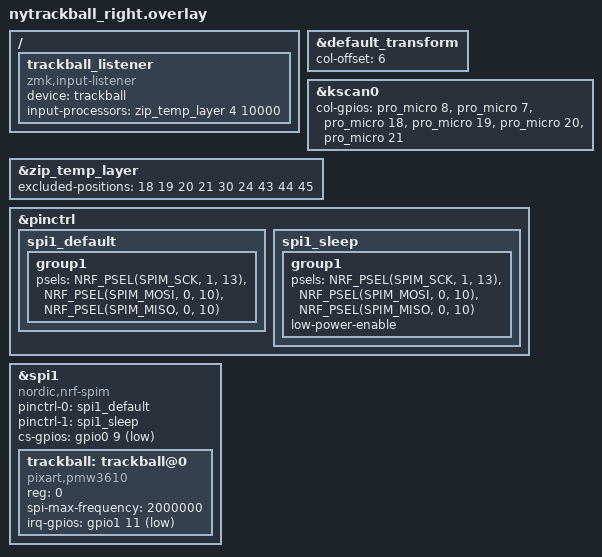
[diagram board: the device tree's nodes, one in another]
/*
 * Copyright (c) 2020 Pete Johanson
 *
 * SPDX-License-Identifier: MIT
 */

#include "nytrackball.dtsi"

&default_transform {
    col-offset = <6>;
};

&kscan0 {
    col-gpios
        = <&pro_micro 8 GPIO_ACTIVE_HIGH>
        , <&pro_micro 7 GPIO_ACTIVE_HIGH>
        , <&pro_micro 18 GPIO_ACTIVE_HIGH>
        , <&pro_micro 19 GPIO_ACTIVE_HIGH>
        , <&pro_micro 20 GPIO_ACTIVE_HIGH>
        , <&pro_micro 21 GPIO_ACTIVE_HIGH>
        ;
};

/ {
    trackball_listener {
        status = "okay";
        compatible = "zmk,input-listener";
        device = <&trackball>;
        input-processors = <&zip_temp_layer 4 10000>;
    };
};

&zip_temp_layer {
    excluded-positions = <
        18 // K(Next)
        19 // T(左クリック)
        20 // N(右クリック)
        21 // S(中クリック)  
        30 // G(Prev)
        24 // Shift
        43 // Left Click
        44 // Mid Click
        45 // Right Click
    >;
};

&pinctrl {
    spi1_default: spi1_default {
        group1 {
            psels = <NRF_PSEL(SPIM_SCK, 1, 13)>,   // 15
                    <NRF_PSEL(SPIM_MOSI, 0, 10)>,  // 16
                    <NRF_PSEL(SPIM_MISO, 0, 10)>;  // 16
        };
    };

    spi1_sleep: spi1_sleep {
        group1 {
            psels = <NRF_PSEL(SPIM_SCK, 1, 13)>,
                    <NRF_PSEL(SPIM_MOSI, 0, 10)>,
                    <NRF_PSEL(SPIM_MISO, 0, 10)>;
            low-power-enable;
        };
    };
};

&spi1 {
    status = "okay";
    compatible = "nordic,nrf-spim";
    pinctrl-0 = <&spi1_default>;
    pinctrl-1 = <&spi1_sleep>;
    pinctrl-names = "default", "sleep";
    cs-gpios = <&gpio0 9 GPIO_ACTIVE_LOW>;  // 10

    trackball: trackball@0 {
        status = "okay";
        compatible = "pixart,pmw3610";
        reg = <0>;
        spi-max-frequency = <2000000>;
        irq-gpios = <&gpio1 11 (GPIO_ACTIVE_LOW | GPIO_PULL_UP)>;  // 14
    };      
};
